# BL808 register map
Vendor: Bouffalo Lab; File version: 0.1
Registers are 32-bit, read-write, reset 0x0 unless marked. A register's access mark holds for its fields unless they carry their own. Offsets are from the block's base; [hi:lo] are bit positions; {n}, {i} and the like mark numbered series.

## PSRAM — Pseudo Static Random Access Memory control
Base 0x20052000
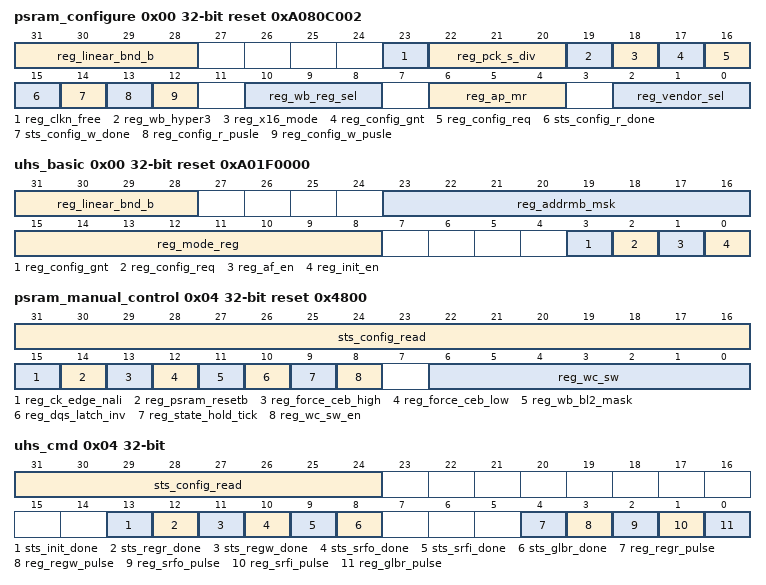
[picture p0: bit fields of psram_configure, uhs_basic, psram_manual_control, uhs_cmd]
0x00 psram_configure reset 0xA080C002
  [31:28] reg_linear_bnd_b, [23] reg_clkn_free, [22:20] reg_pck_s_div, [19] reg_wb_hyper3, [18] reg_x16_mode, [17] reg_config_gnt ro, [16] reg_config_req, [15] sts_config_r_done ro, [14] sts_config_w_done ro, [13] reg_config_r_pusle wo, [12] reg_config_w_pusle wo, [10:8] reg_wb_reg_sel, [6:4] reg_ap_mr, [2:0] reg_vendor_sel
0x00 uhs_basic reset 0xA01F0000
  [31:28] reg_linear_bnd_b, [23:16] reg_addrmb_msk, [15:8] reg_mode_reg, [3] reg_config_gnt ro, [2] reg_config_req, [1] reg_af_en, [0] reg_init_en
0x04 psram_manual_control reset 0x4800
  [31:16] sts_config_read ro, [15] reg_ck_edge_nali, [14] reg_psram_resetb, [13] reg_force_ceb_high, [12] reg_force_ceb_low, [11] reg_wb_bl2_mask, [10] reg_dqs_latch_inv, [9] reg_state_hold_tick, [8] reg_wc_sw_en, [6:0] reg_wc_sw
0x04 uhs_cmd
  [31:24] sts_config_read ro, [13] sts_init_done ro, [12] sts_regr_done ro, [11] sts_regw_done ro, [10] sts_srfo_done ro, [9] sts_srfi_done ro, [8] sts_glbr_done ro, [4] reg_regr_pulse wo, [3] reg_regw_pulse wo, [2] reg_srfo_pulse wo, [1] reg_srfi_pulse wo, [0] reg_glbr_pulse wo
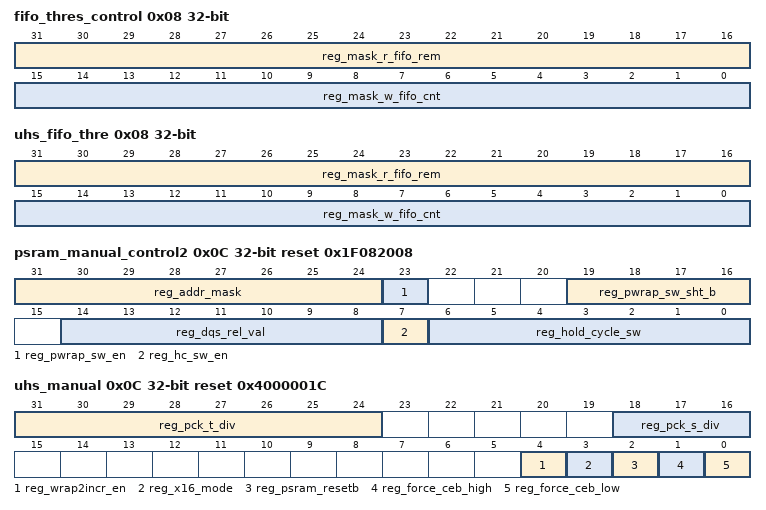
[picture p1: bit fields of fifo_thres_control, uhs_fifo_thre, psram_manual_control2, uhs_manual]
0x08 fifo_thres_control
  [31:16] reg_mask_r_fifo_rem, [15:0] reg_mask_w_fifo_cnt
0x08 uhs_fifo_thre
  [31:16] reg_mask_r_fifo_rem, [15:0] reg_mask_w_fifo_cnt
0x0C psram_manual_control2 reset 0x1F082008
  [31:24] reg_addr_mask, [23] reg_pwrap_sw_en, [19:16] reg_pwrap_sw_sht_b, [14:8] reg_dqs_rel_val, [7] reg_hc_sw_en, [6:0] reg_hold_cycle_sw
0x0C uhs_manual reset 0x4000001C
  [31:24] reg_pck_t_div, [18:16] reg_pck_s_div, [4] reg_wrap2incr_en, [3] reg_x16_mode, [2] reg_psram_resetb, [1] reg_force_ceb_high, [0] reg_force_ceb_low
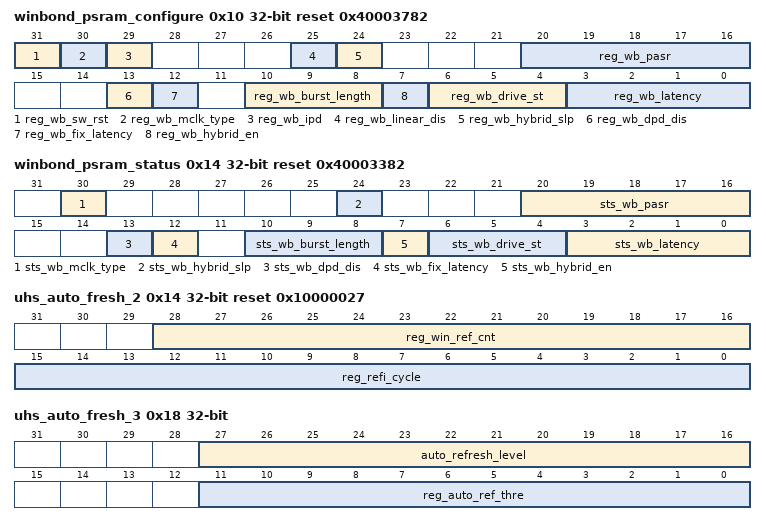
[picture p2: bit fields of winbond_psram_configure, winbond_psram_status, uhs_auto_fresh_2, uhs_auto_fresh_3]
0x10 winbond_psram_configure reset 0x40003782
  [31] reg_wb_sw_rst, [30] reg_wb_mclk_type, [29] reg_wb_ipd, [25] reg_wb_linear_dis, [24] reg_wb_hybrid_slp, [20:16] reg_wb_pasr, [13] reg_wb_dpd_dis, [12] reg_wb_fix_latency, [10:8] reg_wb_burst_length, [7] reg_wb_hybrid_en, [6:4] reg_wb_drive_st, [3:0] reg_wb_latency
0x10 uhs_auto_fresh_1 reset 0x27100
  [27:0] reg_win_cycle
0x14 winbond_psram_status reset 0x40003382
  [30] sts_wb_mclk_type ro, [24] sts_wb_hybrid_slp ro, [20:16] sts_wb_pasr ro, [13] sts_wb_dpd_dis ro, [12] sts_wb_fix_latency ro, [10:8] sts_wb_burst_length ro, [7] sts_wb_hybrid_en ro, [6:4] sts_wb_drive_st ro, [3:0] sts_wb_latency ro
0x14 uhs_auto_fresh_2 reset 0x10000027
  [28:16] reg_win_ref_cnt, [15:0] reg_refi_cycle
0x18 winbond_psram_configure2
  [3:0] reg_wb_zq_code
0x18 uhs_auto_fresh_3
  [27:16] auto_refresh_level ro, [11:0] reg_auto_ref_thre
0x1C uhs_auto_fresh_4 reset 0x1D
  [6:0] reg_bust_cycle
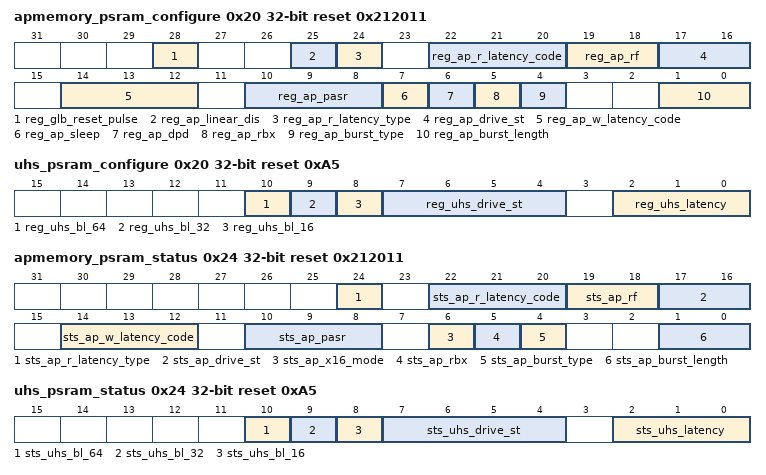
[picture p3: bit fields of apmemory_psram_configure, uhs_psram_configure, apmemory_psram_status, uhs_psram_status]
0x20 apmemory_psram_configure reset 0x212011
  [28] reg_glb_reset_pulse wo, [25] reg_ap_linear_dis, [24] reg_ap_r_latency_type, [22:20] reg_ap_r_latency_code, [19:18] reg_ap_rf, [17:16] reg_ap_drive_st, [14:12] reg_ap_w_latency_code, [10:8] reg_ap_pasr, [7] reg_ap_sleep, [6] reg_ap_dpd, [5] reg_ap_rbx, [4] reg_ap_burst_type, [1:0] reg_ap_burst_length
0x20 uhs_psram_configure reset 0xA5
  [10] reg_uhs_bl_64, [9] reg_uhs_bl_32, [8] reg_uhs_bl_16, [7:4] reg_uhs_drive_st, [2:0] reg_uhs_latency
0x24 apmemory_psram_status reset 0x212011
  [24] sts_ap_r_latency_type ro, [22:20] sts_ap_r_latency_code ro, [19:18] sts_ap_rf ro, [17:16] sts_ap_drive_st ro, [14:12] sts_ap_w_latency_code ro, [10:8] sts_ap_pasr ro, [6] sts_ap_x16_mode ro, [5] sts_ap_rbx ro, [4] sts_ap_burst_type ro, [1:0] sts_ap_burst_length ro
0x24 uhs_psram_status reset 0xA5
  [10] sts_uhs_bl_64 ro, [9] sts_uhs_bl_32 ro, [8] sts_uhs_bl_16 ro, [7:4] sts_uhs_drive_st ro, [2:0] sts_uhs_latency ro
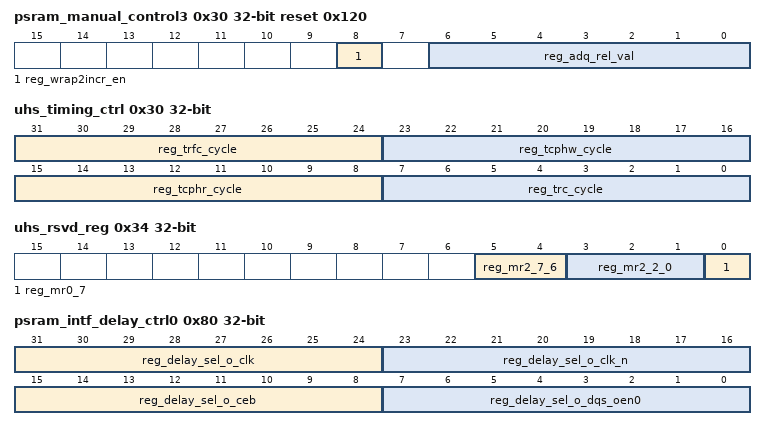
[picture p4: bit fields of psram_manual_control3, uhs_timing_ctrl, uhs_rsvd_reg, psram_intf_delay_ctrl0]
0x30 psram_manual_control3 reset 0x120
  [8] reg_wrap2incr_en, [6:0] reg_adq_rel_val
0x30 uhs_timing_ctrl
  [31:24] reg_trfc_cycle, [23:16] reg_tcphw_cycle, [15:8] reg_tcphr_cycle, [7:0] reg_trc_cycle
0x34 uhs_rsvd_reg
  [5:4] reg_mr2_7_6, [3:1] reg_mr2_2_0, [0] reg_mr0_7
0x80 psram_intf_delay_ctrl0
  [31:24] reg_delay_sel_o_clk, [23:16] reg_delay_sel_o_clk_n, [15:8] reg_delay_sel_o_ceb, [7:0] reg_delay_sel_o_dqs_oen0
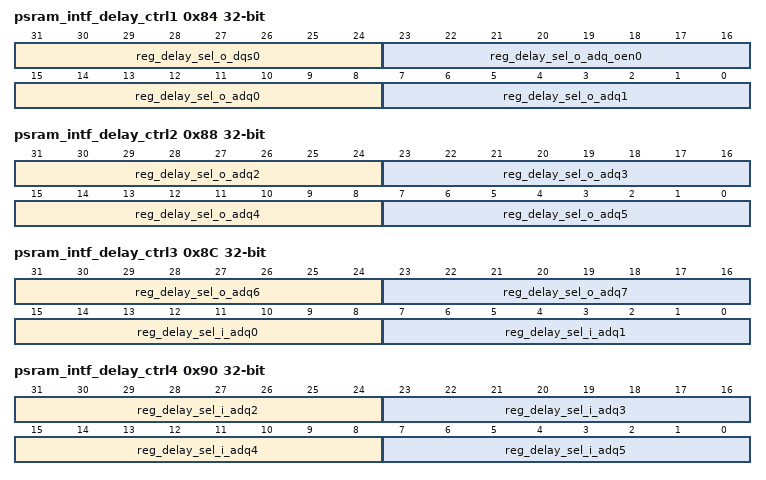
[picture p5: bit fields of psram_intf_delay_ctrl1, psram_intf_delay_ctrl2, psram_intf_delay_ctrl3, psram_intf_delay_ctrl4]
0x84 psram_intf_delay_ctrl1
  [31:24] reg_delay_sel_o_dqs0, [23:16] reg_delay_sel_o_adq_oen0, [15:8] reg_delay_sel_o_adq0, [7:0] reg_delay_sel_o_adq1
0x88 psram_intf_delay_ctrl2
  [47-8n:40-8n] reg_delay_sel_o_adq{n} (n=2..5)
0x8C psram_intf_delay_ctrl3
  [31:24] reg_delay_sel_o_adq6, [23:16] reg_delay_sel_o_adq7, [15:8] reg_delay_sel_i_adq0, [7:0] reg_delay_sel_i_adq1
0x90 psram_intf_delay_ctrl4
  [47-8n:40-8n] reg_delay_sel_i_adq{n} (n=2..5)
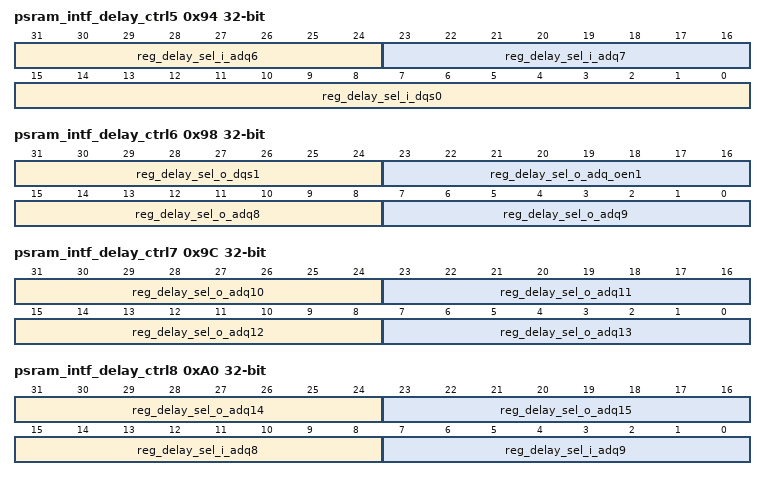
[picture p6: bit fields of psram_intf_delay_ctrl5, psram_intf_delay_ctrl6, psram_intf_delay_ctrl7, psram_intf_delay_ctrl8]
0x94 psram_intf_delay_ctrl5
  [31:24] reg_delay_sel_i_adq6, [23:16] reg_delay_sel_i_adq7, [15:0] reg_delay_sel_i_dqs0
0x98 psram_intf_delay_ctrl6
  [31:24] reg_delay_sel_o_dqs1, [23:16] reg_delay_sel_o_adq_oen1, [15:8] reg_delay_sel_o_adq8, [7:0] reg_delay_sel_o_adq9
0x9C psram_intf_delay_ctrl7
  [111-8n:104-8n] reg_delay_sel_o_adq{n} (n=10..13)
0xA0 psram_intf_delay_ctrl8
  [31:24] reg_delay_sel_o_adq14, [23:16] reg_delay_sel_o_adq15, [15:8] reg_delay_sel_i_adq8, [7:0] reg_delay_sel_i_adq9
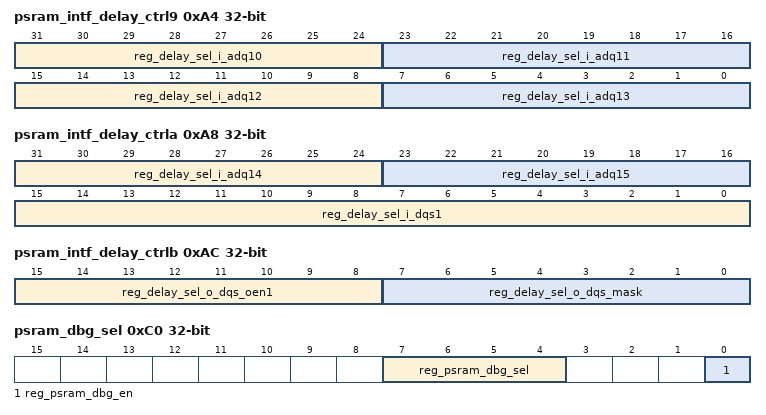
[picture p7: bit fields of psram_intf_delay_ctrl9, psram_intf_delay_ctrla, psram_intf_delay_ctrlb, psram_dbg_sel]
0xA4 psram_intf_delay_ctrl9
  [111-8n:104-8n] reg_delay_sel_i_adq{n} (n=10..13)
0xA8 psram_intf_delay_ctrla
  [31:24] reg_delay_sel_i_adq14, [23:16] reg_delay_sel_i_adq15, [15:0] reg_delay_sel_i_dqs1
0xAC psram_intf_delay_ctrlb
  [15:8] reg_delay_sel_o_dqs_oen1, [7:0] reg_delay_sel_o_dqs_mask
0xC0 psram_dbg_sel
  [7:4] reg_psram_dbg_sel, [0] reg_psram_dbg_en
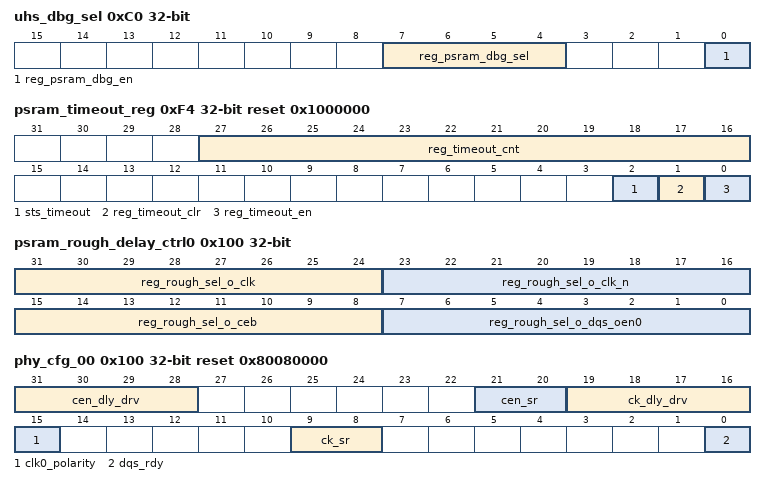
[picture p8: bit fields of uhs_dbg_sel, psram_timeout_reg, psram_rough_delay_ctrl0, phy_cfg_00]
0xC0 uhs_dbg_sel
  [7:4] reg_psram_dbg_sel, [0] reg_psram_dbg_en
0xF0 psram_dummy_reg reset 0xFFFF0000
  [31:0] reg_psram_dummy_reg
0xF0 uhs_dummy_reg reset 0xFFFF0000
  [31:0] reg_psram_dummy_reg
0xF4 psram_timeout_reg reset 0x1000000
  [27:16] reg_timeout_cnt, [2] sts_timeout ro, [1] reg_timeout_clr, [0] reg_timeout_en
0x100 psram_rough_delay_ctrl0
  [31:24] reg_rough_sel_o_clk, [23:16] reg_rough_sel_o_clk_n, [15:8] reg_rough_sel_o_ceb, [7:0] reg_rough_sel_o_dqs_oen0
0x100 phy_cfg_00 reset 0x80080000
  [31:28] cen_dly_drv, [21:20] cen_sr, [19:16] ck_dly_drv, [15] clk0_polarity, [9:8] ck_sr, [0] dqs_rdy ro
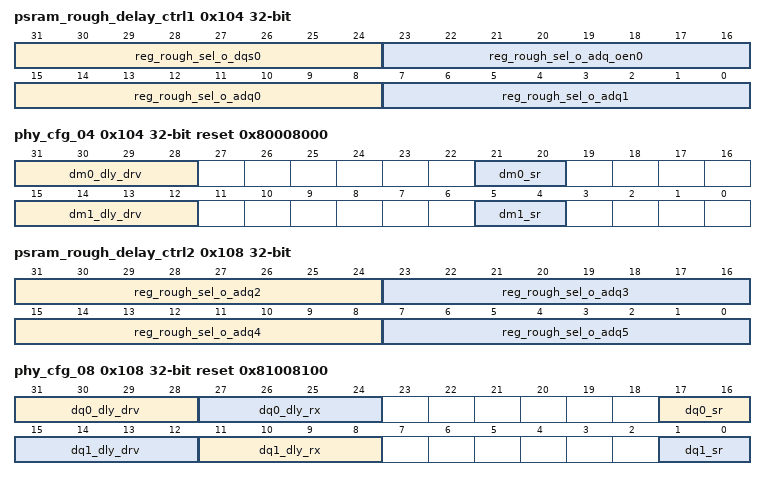
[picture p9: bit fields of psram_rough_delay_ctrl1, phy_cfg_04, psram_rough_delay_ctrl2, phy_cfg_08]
0x104 psram_rough_delay_ctrl1
  [31:24] reg_rough_sel_o_dqs0, [23:16] reg_rough_sel_o_adq_oen0, [15:8] reg_rough_sel_o_adq0, [7:0] reg_rough_sel_o_adq1
0x104 phy_cfg_04 reset 0x80008000
  [31:28] dm0_dly_drv, [21:20] dm0_sr, [15:12] dm1_dly_drv, [5:4] dm1_sr
0x108 psram_rough_delay_ctrl2
  [47-8n:40-8n] reg_rough_sel_o_adq{n} (n=2..5)
0x108 phy_cfg_08 reset 0x81008100
  [31:28] dq0_dly_drv, [27:24] dq0_dly_rx, [17:16] dq0_sr, [15:12] dq1_dly_drv, [11:8] dq1_dly_rx, [1:0] dq1_sr
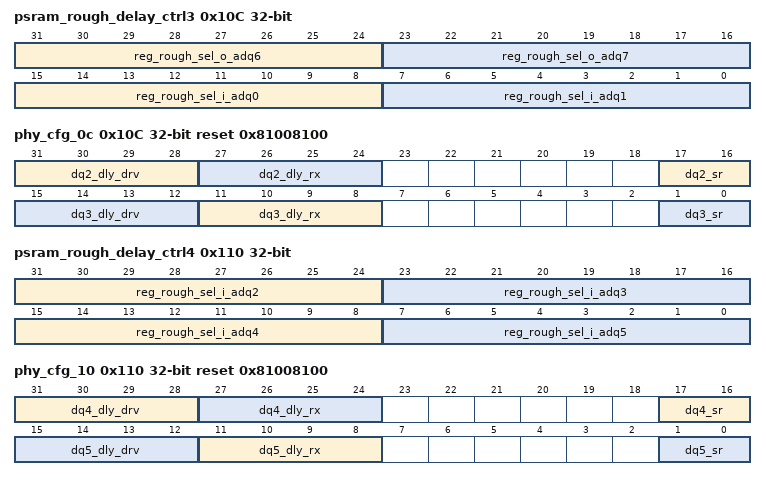
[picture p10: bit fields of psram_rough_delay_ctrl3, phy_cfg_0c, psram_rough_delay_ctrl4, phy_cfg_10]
0x10C psram_rough_delay_ctrl3
  [31:24] reg_rough_sel_o_adq6, [23:16] reg_rough_sel_o_adq7, [15:8] reg_rough_sel_i_adq0, [7:0] reg_rough_sel_i_adq1
0x10C phy_cfg_0c reset 0x81008100
  [31:28] dq2_dly_drv, [27:24] dq2_dly_rx, [17:16] dq2_sr, [15:12] dq3_dly_drv, [11:8] dq3_dly_rx, [1:0] dq3_sr
0x110 psram_rough_delay_ctrl4
  [47-8n:40-8n] reg_rough_sel_i_adq{n} (n=2..5)
0x110 phy_cfg_10 reset 0x81008100
  [31:28] dq4_dly_drv, [27:24] dq4_dly_rx, [17:16] dq4_sr, [15:12] dq5_dly_drv, [11:8] dq5_dly_rx, [1:0] dq5_sr
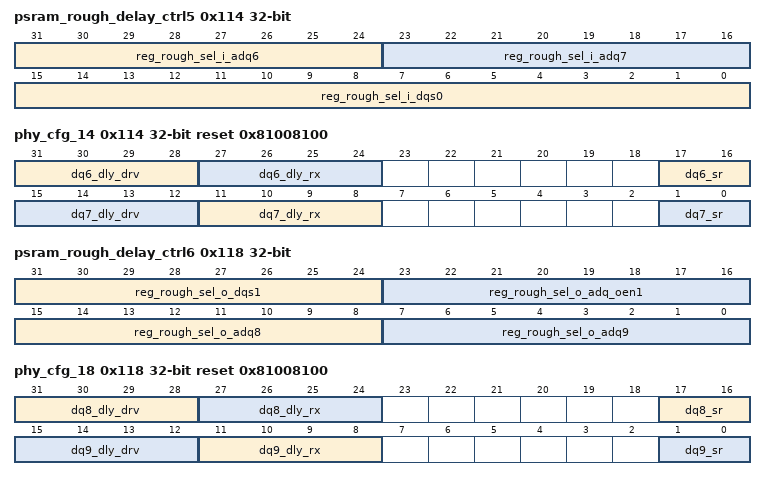
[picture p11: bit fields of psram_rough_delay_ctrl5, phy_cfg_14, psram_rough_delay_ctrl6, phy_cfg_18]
0x114 psram_rough_delay_ctrl5
  [31:24] reg_rough_sel_i_adq6, [23:16] reg_rough_sel_i_adq7, [15:0] reg_rough_sel_i_dqs0
0x114 phy_cfg_14 reset 0x81008100
  [31:28] dq6_dly_drv, [27:24] dq6_dly_rx, [17:16] dq6_sr, [15:12] dq7_dly_drv, [11:8] dq7_dly_rx, [1:0] dq7_sr
0x118 psram_rough_delay_ctrl6
  [31:24] reg_rough_sel_o_dqs1, [23:16] reg_rough_sel_o_adq_oen1, [15:8] reg_rough_sel_o_adq8, [7:0] reg_rough_sel_o_adq9
0x118 phy_cfg_18 reset 0x81008100
  [31:28] dq8_dly_drv, [27:24] dq8_dly_rx, [17:16] dq8_sr, [15:12] dq9_dly_drv, [11:8] dq9_dly_rx, [1:0] dq9_sr
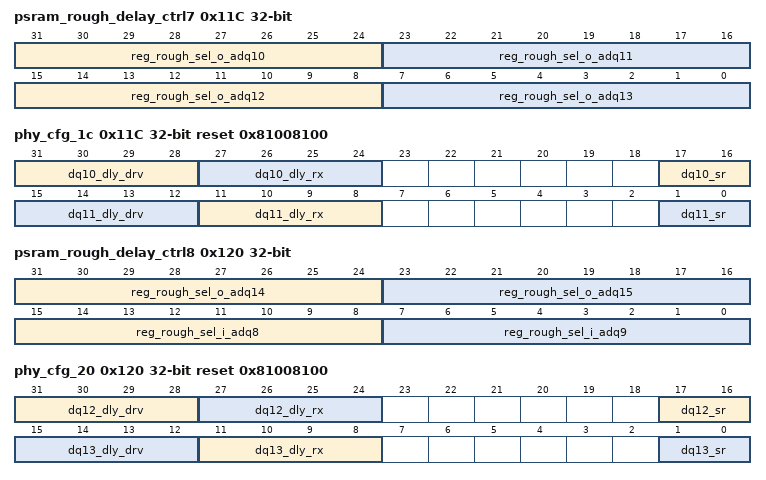
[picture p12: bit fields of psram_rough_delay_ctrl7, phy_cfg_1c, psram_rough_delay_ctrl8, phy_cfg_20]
0x11C psram_rough_delay_ctrl7
  [111-8n:104-8n] reg_rough_sel_o_adq{n} (n=10..13)
0x11C phy_cfg_1c reset 0x81008100
  [31:28] dq10_dly_drv, [27:24] dq10_dly_rx, [17:16] dq10_sr, [15:12] dq11_dly_drv, [11:8] dq11_dly_rx, [1:0] dq11_sr
0x120 psram_rough_delay_ctrl8
  [31:24] reg_rough_sel_o_adq14, [23:16] reg_rough_sel_o_adq15, [15:8] reg_rough_sel_i_adq8, [7:0] reg_rough_sel_i_adq9
0x120 phy_cfg_20 reset 0x81008100
  [31:28] dq12_dly_drv, [27:24] dq12_dly_rx, [17:16] dq12_sr, [15:12] dq13_dly_drv, [11:8] dq13_dly_rx, [1:0] dq13_sr
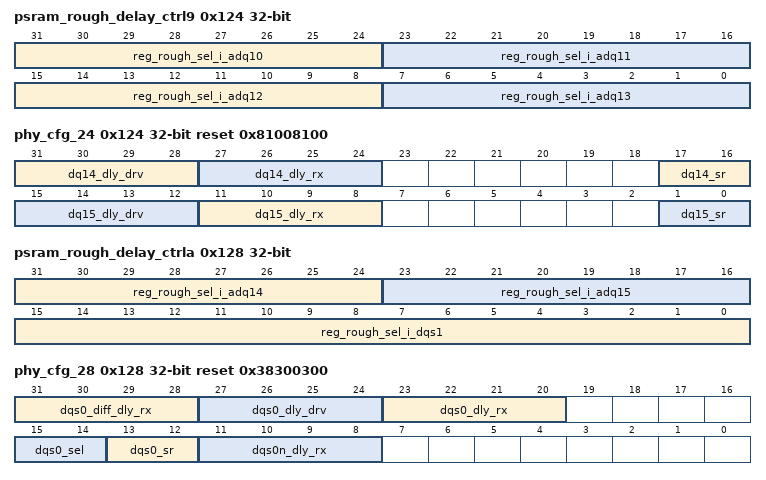
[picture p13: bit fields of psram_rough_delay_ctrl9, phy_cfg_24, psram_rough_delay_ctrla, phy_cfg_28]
0x124 psram_rough_delay_ctrl9
  [111-8n:104-8n] reg_rough_sel_i_adq{n} (n=10..13)
0x124 phy_cfg_24 reset 0x81008100
  [31:28] dq14_dly_drv, [27:24] dq14_dly_rx, [17:16] dq14_sr, [15:12] dq15_dly_drv, [11:8] dq15_dly_rx, [1:0] dq15_sr
0x128 psram_rough_delay_ctrla
  [31:24] reg_rough_sel_i_adq14, [23:16] reg_rough_sel_i_adq15, [15:0] reg_rough_sel_i_dqs1
0x128 phy_cfg_28 reset 0x38300300
  [31:28] dqs0_diff_dly_rx, [27:24] dqs0_dly_drv, [23:20] dqs0_dly_rx, [15:14] dqs0_sel, [13:12] dqs0_sr, [11:8] dqs0n_dly_rx
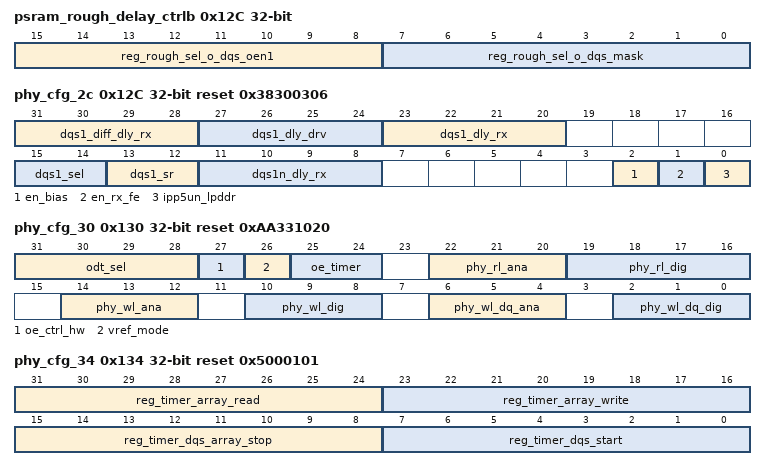
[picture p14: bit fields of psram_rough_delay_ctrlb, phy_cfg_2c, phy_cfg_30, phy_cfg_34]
0x12C psram_rough_delay_ctrlb
  [15:8] reg_rough_sel_o_dqs_oen1, [7:0] reg_rough_sel_o_dqs_mask
0x12C phy_cfg_2c reset 0x38300306
  [31:28] dqs1_diff_dly_rx, [27:24] dqs1_dly_drv, [23:20] dqs1_dly_rx, [15:14] dqs1_sel, [13:12] dqs1_sr, [11:8] dqs1n_dly_rx, [2] en_bias, [1] en_rx_fe, [0] ipp5un_lpddr
0x130 phy_cfg_30 reset 0xAA331020
  [31:28] odt_sel, [27] oe_ctrl_hw, [26] vref_mode, [25:24] oe_timer, [22:20] phy_rl_ana, [19:16] phy_rl_dig, [14:12] phy_wl_ana, [10:8] phy_wl_dig, [6:4] phy_wl_dq_ana, [2:0] phy_wl_dq_dig
0x134 phy_cfg_34 reset 0x5000101
  [31:24] reg_timer_array_read, [23:16] reg_timer_array_write, [15:8] reg_timer_dqs_array_stop, [7:0] reg_timer_dqs_start
0x138 phy_cfg_38 reset 0x2080107
  [31:24] reg_timer_dqs_stop, [23:16] reg_timer_reg_read, [15:8] reg_timer_reg_write, [7:0] reg_timer_auto_refresh
0x13C phy_cfg_3c reset 0x2720808
  [29:16] reg_timer_global_rst, [15:8] reg_timer_self_refresh1_exit, [7:0] reg_timer_self_refresh1_in
0x140 phy_cfg_40 reset 0xA2FF0000
  [31] uhs_phy_dqs_diff, [30] uhs_dc_tp_out_en, [29] tx_clktree_gate_hw, [27] ten_uhs_phy_dig, [26] ten_uhs_phy, [25] soc_en_aon, [24] reg_uhs_phy_ten, [23:16] reg_uhs_dmy1, [15:8] reg_uhs_dmy0, [7:4] vref_dq_sel, [3:0] vref_sel
0x144 phy_cfg_44 reset 0x40B0308
  [31:24] reg_timer_reg_write_busy, [23:16] reg_timer_reg_read_busy, [15:8] reg_timer_array_write_busy, [7:0] reg_timer_array_read_busy
0x148 phy_cfg_48 reset 0x208908
  [23:20] en_rx_fe_dly, [19] force_fsm, [18:16] reg_test_mux_sel, [15] en_rx_fe_hw, [14:12] reg_test_div_sel, [11] pu_uhs_pw1p8, [9:8] psram_type, [6:4] tmux_uhs_phy_dig, [3] chip_en_33, [2:0] tmux
0x14C phy_cfg_4c reset 0x130000
  [20] odt_sel_hw, [19:16] odt_sel_dly, [15:0] tout_uhs_phy_dig ro
0x150 phy_cfg_50 reset 0x1444444
  [26:24] phy_wl_cen_ana, [22:20] dq_oe_dn_n_reg, [18:16] dq_oe_dn_p_reg, [14:12] dq_oe_mid_n_reg, [10:8] dq_oe_mid_p_reg, [6:4] dq_oe_up_n_reg, [2:0] dq_oe_up_p_reg
